# GD32H75E register map
File version: 1.0
CPU: CM7 r1p2, little endian, MPU, FPU, 4 interrupt priority bits
Registers are 32-bit, read-write, reset 0x0 unless marked. A register's access mark holds for its fields unless they carry their own. Offsets are from the block's base; [hi:lo] are bit positions; {n}, {i} and the like mark numbered series; 'fields as' and 'values as' point back to an identical list.

## PMU — Power management unit
Base 0x58005800
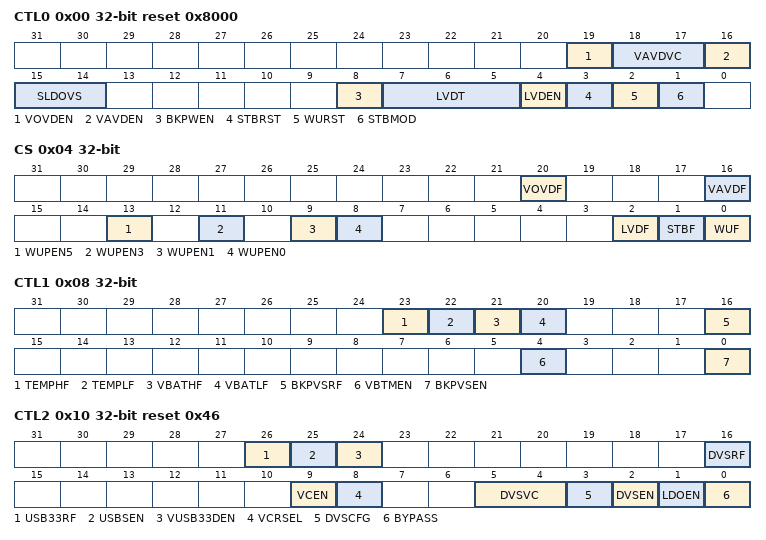
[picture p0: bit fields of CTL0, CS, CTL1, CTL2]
0x00 CTL0 reset 0x8000 — Control register 0
  [19] VOVDEN — Peripheral voltage on V0.9V detector enable bit
  [18:17] VAVDVC — VDDA analog voltage detector voltage level configure bits
  [16] VAVDEN — VDDA analog voltage detector voltage enable bit
  [15:14] SLDOVS — Deep-sleep mode voltage scaling selection
  [8] BKPWEN — Backup domain write enable bit
  [7:5] LVDT — Low voltage detector threshold
  [4] LVDEN — Low voltage detector enable bit
  [3] STBRST — Standby flag reset bit
  [2] WURST — Wakeup flag reset bit
  [1] STBMOD — Standby Mode
0x04 CS access per field — Control and status register
  [20] VOVDF ro — Peripheral voltage on V0.9V detector flag bit
  [16] VAVDF ro — VDDA analog voltage detector voltage output on VDDA flag bit
  [13] WUPEN5 rw — WKUP Pin5 (PC1) enable
  [11] WUPEN3 rw — WKUP pin3 (PC13) enable
  [9] WUPEN1 rw — WKUP pin1 (PA2) enable
  [8] WUPEN0 rw — WKUP pin0 (PA0) enable
  [2] LVDF ro — Low voltage detector status flag
  [1] STBF ro — Standby flag
  [0] WUF ro — Wakeup Flag
0x08 CTL1 access per field — Control register 1
  [23] TEMPHF ro — Temperature level monitoring versus high threshold
  [22] TEMPLF ro — Temperature level monitoring versus low threshold
  [21] VBATHF ro — VBAT level monitoring versus high threshold
  [20] VBATLF ro — VBAT level monitoring versus low threshold
  [16] BKPVSRF ro — Backup voltage stabilizer ready flag
  [4] VBTMEN rw — VBAT and temperature monitoring enable.
  [0] BKPVSEN rw — Backup voltage stabilizer enable
0x10 CTL2 access per field reset 0x46 — Control register 2
  [26] USB33RF ro — USB supply ready flag bit
  [25] USBSEN rw — USB voltage stabilizer enable.
  [24] VUSB33DEN rw — VDD33USB voltage level detector enable bit
  [16] DVSRF ro — Step-down voltage stabilizer ready flag bit
  [9] VCEN rw — VBAT battery charging enable
  [8] VCRSEL rw — VBAT battery charging resistor selection
  [5:4] DVSVC rw — Step-down voltage stabilizer output voltage level configure bits
  [3] DVSCFG rw — Step-down voltage stabilizer forced on and in High Power MR mode.
  [2] DVSEN rw — Step-down voltage stabilizer enable bit
  [1] LDOEN rw — Low drop-out voltage stabilizer enable bit
  [0] BYPASS rw — Power management unit bypass control bit
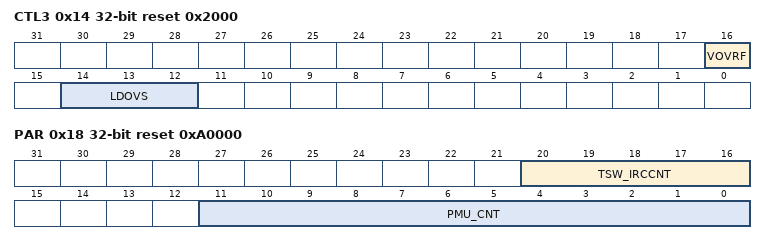
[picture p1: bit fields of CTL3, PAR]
0x14 CTL3 access per field reset 0x2000 — Control register 3
  [16] VOVRF ro — V0.9V voltage ready bit
  [14:12] LDOVS rw — LDO output voltage select
0x18 PAR reset 0xA0000 — Parameter register
  [20:16] TSW_IRCCNT — When enter Deep-sleep, switch to LPIRC4M / IRC64M (confirmed by DSPWUSSEL) clock. Wait the LPIRC4M / IRC64M (confirmed by DSPWUSSEL) counter and then set Deep-sleep mode. The default is 10 clocks.
  [11:0] PMU_CNT — Exit Deep-sleep mode wait time count configure bits

## RAMECCMU0 — RAM ECC monitor unit0
Base 0x52009000
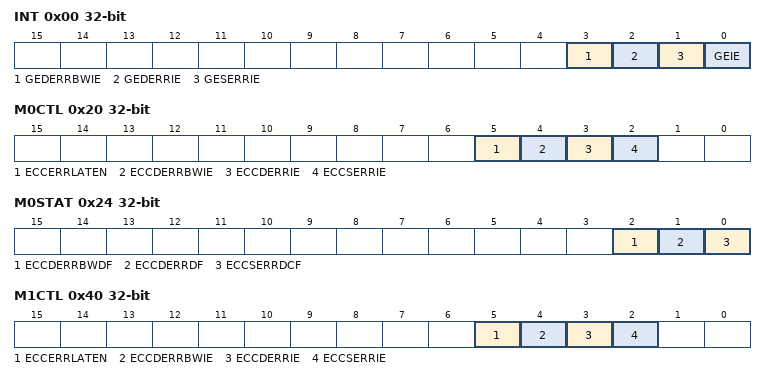
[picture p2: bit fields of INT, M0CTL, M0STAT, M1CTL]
0x00 INT — RAMECCMU global interruput register
  [3] GEDERRBWIE — Global ECC double error on byte write interrupt enable
  [2] GEDERRIE — Global ECC double error interrupt enable
  [1] GESERRIE — Global ECC single error interrupt enable
  [0] GEIE — Global ECC interrupt enable
0x20 M0CTL — monitor 0 control register
  [5] ECCERRLATEN — ECC error latching enable
  [4] ECCDERRBWIE — ECC double error on byte write interrupt enable
  [3] ECCDERRIE — ECC double error interrupt enable
  [2] ECCSERRIE — ECC single error interrupt enable
0x24 M0STAT — monitor 0 status register
  [2] ECCDERRBWDF — ECC double error on byte write detected flag
  [1] ECCDERRDF — ECC double error detected flag
  [0] ECCSERRDCF — ECC single error detected and corrected flag
0x28 M0FADDR ro — monitor 0 failing address register
  [31:0] ECCFADDR — ECC error failing address
0x2C M0FDL ro — monitor 0 failing data low register
  [31:0] ECCFDL — ECC failing data low bits
{0x30+0x20*i} M{i}FDH ro (i=0..4) — monitor 0 failing data high register
  [31:0] ECCFDH — ECC failing data high bitss
0x34 M0FECODE ro — monitor 0 failing ECC error code register
  [31:0] ECCFECODE — ECC failing error code
0x40 M1CTL — monitor 1 control register
  fields as M0CTL
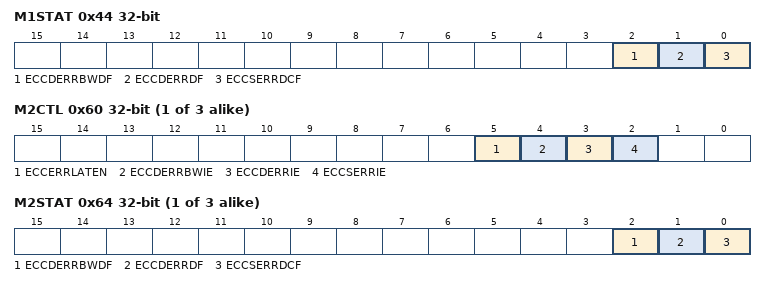
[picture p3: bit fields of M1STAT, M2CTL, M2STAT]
0x44 M1STAT — monitor 1 status register
  fields as M0STAT
0x48 M1FADDR ro — monitor 1 failing address register
  [31:0] ECCFADDR — ECC error failing address
0x4C M1FDL ro — monitor 1 failing data low register
  [31:0] ECCFDL — ECC failing data low bits
0x54 M1FECODE ro — monitor 1 failing ECC error code register
  [31:0] ECCFECODE — ECC failing error code
{0x20+0x20*i} M{i}CTL (i=2..4) — monitor 0 control register
  fields as M0CTL
{0x24+0x20*i} M{i}STAT (i=2..4) — monitor 0 status register
  fields as M0STAT
{0x28+0x20*i} M{i}FADDR ro (i=2..4) — monitor 0 failing address register
  [31:0] ECCFADDR — ECC error failing address
{0x2C+0x20*i} M{i}FDL ro (i=2..4) — monitor 0 failing data low register
  [31:0] ECCFDL — ECC failing data low bits
{0x34+0x20*i} M{i}FECODE ro (i=2..4) — monitor 0 failing ECC error code register
  [31:0] ECCFECODE — ECC failing error code

## RAMECCMU1 — RAM ECC monitor unit 1
Base 0x48023000
Registers as RAMECCMU0, without M3CTL, M3STAT, M3FADDR, M3FDL, M3FDH, M3FECODE, M4CTL, M4STAT, M4FADDR, M4FDL, M4FDH, M4FECODE.
